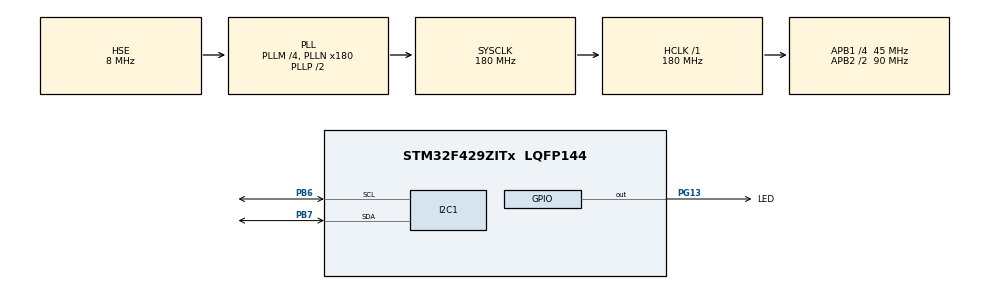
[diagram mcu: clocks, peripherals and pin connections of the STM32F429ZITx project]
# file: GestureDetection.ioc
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Mcu.Family=STM32F4
Mcu.Name=STM32F429ZITx
Mcu.Package=LQFP144
NVIC.PriorityGroup=NVIC_PRIORITYGROUP_4
PB6.Mode=I2C
PB6.Signal=I2C1_SCL
PB7.Mode=I2C
PB7.Signal=I2C1_SDA
PG13.GPIO_Label=LED
PG13.Signal=GPIO_Output
PH0/OSC_IN.Mode=HSE-External-Oscillator
PH0/OSC_IN.Signal=RCC_OSC_IN
PH1/OSC_OUT.Mode=HSE-External-Oscillator
PH1/OSC_OUT.Signal=RCC_OSC_OUT
ProjectManager.HeapSize=0x200
ProjectManager.StackSize=0x400
ProjectManager.TargetToolchain=SW4STM32
RCC.48MHZClocksFreq_Value=90000000
RCC.AHBFreq_Value=180000000
RCC.APB1CLKDivider=RCC_HCLK_DIV4
RCC.APB1Freq_Value=45000000
RCC.APB1TimFreq_Value=90000000
RCC.APB2CLKDivider=RCC_HCLK_DIV2
RCC.APB2Freq_Value=90000000
RCC.APB2TimFreq_Value=180000000
RCC.CortexFreq_Value=180000000
RCC.HCLKFreq_Value=180000000
RCC.HSE_VALUE=8000000
RCC.HSI_VALUE=16000000
RCC.LSE_VALUE=32768
RCC.PLLM=4
RCC.PLLN=180
RCC.PLLSourceVirtual=RCC_PLLSOURCE_HSE
RCC.SYSCLKFreq_VALUE=180000000
RCC.SYSCLKSource=RCC_SYSCLKSOURCE_PLLCLK
RCC.VCOOutputFreq_Value=360000000
board=GestureDetection

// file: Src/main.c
/**
  ******************************************************************************
  * @file           : main.c
  * @brief          : Main program body
  ******************************************************************************
  ** This notice applies to any and all portions of this file
  * that are not between comment pairs USER CODE BEGIN and
  * USER CODE END. Other portions of this file, whether
  * inserted by the user or by software development tools
  * are owned by their respective copyright owners.
  *
  * COPYRIGHT(c) 2018 STMicroelectronics
  *
  * Redistribution and use in source and binary forms, with or without modification,
  * are permitted provided that the following conditions are met:
  *   1. Redistributions of source code must retain the above copyright notice,
  *      this list of conditions and the following disclaimer.
  *   2. Redistributions in binary form must reproduce the above copyright notice,
  *      this list of conditions and the following disclaimer in the documentation
  *      and/or other materials provided with the distribution.
  *   3. Neither the name of STMicroelectronics nor the names of its contributors
  *      may be used to endorse or promote products derived from this software
  *      without specific prior written permission.
  *
  * THIS SOFTWARE IS PROVIDED BY THE COPYRIGHT HOLDERS AND CONTRIBUTORS "AS IS"
  * AND ANY EXPRESS OR IMPLIED WARRANTIES, INCLUDING, BUT NOT LIMITED TO, THE
  * IMPLIED WARRANTIES OF MERCHANTABILITY AND FITNESS FOR A PARTICULAR PURPOSE ARE
  * DISCLAIMED. IN NO EVENT SHALL THE COPYRIGHT HOLDER OR CONTRIBUTORS BE LIABLE
  * FOR ANY DIRECT, INDIRECT, INCIDENTAL, SPECIAL, EXEMPLARY, OR CONSEQUENTIAL
  * DAMAGES (INCLUDING, BUT NOT LIMITED TO, PROCUREMENT OF SUBSTITUTE GOODS OR
  * SERVICES; LOSS OF USE, DATA, OR PROFITS; OR BUSINESS INTERRUPTION) HOWEVER
  * CAUSED AND ON ANY THEORY OF LIABILITY, WHETHER IN CONTRACT, STRICT LIABILITY,
  * OR TORT (INCLUDING NEGLIGENCE OR OTHERWISE) ARISING IN ANY WAY OUT OF THE USE
  * OF THIS SOFTWARE, EVEN IF ADVISED OF THE POSSIBILITY OF SUCH DAMAGE.
  *
  ******************************************************************************
  */
#include "main.h"
#include "stm32f4xx_hal.h"

/* USER CODE BEGIN Includes */
#include "Sensor.h"
/* USER CODE END Includes */

I2C_HandleTypeDef hi2c1;

/* USER CODE BEGIN PV */
/* Private variables ---------------------------------------------------------*/
//#define APDS9960_ADDRESS 0x39
/* USER CODE END PV */

void SystemClock_Config(void);
static void MX_GPIO_Init(void);
static void MX_I2C1_Init(void);

/* USER CODE BEGIN PFP */
/* Private function prototypes -----------------------------------------------*/

/* USER CODE END PFP */

int main(void)
{
  /* USER CODE BEGIN 1 */
	uint8_t data;
//	uint8_t i;
  /* USER CODE END 1 */

  /* MCU Configuration----------------------------------------------------------*/

  /* Reset of all peripherals, Initializes the Flash interface and the Systick. */
  HAL_Init();

  /* Configure the system clock */
  SystemClock_Config();

  /* Initialize all configured peripherals */
  MX_GPIO_Init();
  MX_I2C1_Init();
  /* USER CODE BEGIN 2 */
//  data[0] = APDS9960_ENABLE;
//  data[1] = 0x01;
//
//  if(HAL_I2C_Master_Transmit(&hi2c3,APDS9960_I2C_ADDRESS,data,2,10) == HAL_OK)
//	  HAL_GPIO_TogglePin(GPIOG, GPIO_PIN_13);
//
//  data[0] = APDS9960_ENABLE;
//  if(HAL_I2C_Master_Transmit(&hi2c3,APDS9960_I2C_ADDRESS,data,1,10) == HAL_OK)
//	  HAL_GPIO_TogglePin(GPIOG, GPIO_PIN_13);
//
//  data[1] = 0x00;
//  if(HAL_I2C_Master_Receive(&hi2c3,APDS9960_I2C_ADDRESS,&data[1],1,10) == HAL_OK)
//	  HAL_GPIO_TogglePin(GPIOG, GPIO_PIN_13);
//  if(data[1]==0x01)
//	  HAL_GPIO_TogglePin(GPIOG, GPIO_PIN_13);

//
//  data = 0x01;
//  HAL_I2C_Mem_Write(&hi2c3,APDS9960_I2C_ADDRESS,APDS9960_ENABLE,1,&data,1,100);
  //  for(i=0;i<255;i++){
//	  if(HAL_I2C_IsDeviceReady(&hi2c3,APDS9960_I2C_ADDRESS,5,100) == HAL_OK)
//		  HAL_GPIO_TogglePin(GPIOG, GPIO_PIN_13);
//  }
//  HAL_I2C_Mem_Read(&hi2c3, APDS9960_I2C_ADDRESS, APDS9960_DEVICE_ID, 1, &data, 1, 100);
//
//  if(data == 0x01){		//DEVICE_ID = 0xAB || 0x9C
//	  HAL_GPIO_TogglePin(GPIOG, GPIO_PIN_13);
//  }
  /* USER CODE END 2 */

  /* Infinite loop */
  while (1)
  {

  /* USER CODE BEGIN 3 */
	  /*Mozliwe przyczyny braku polaczenia z sensorem:
	   * - zle ustawiona predkosc i2c
	   * - nalezy najpierw aktywowac sensor (cos mu wyslac)
	   * - funkcja i2c_HAL nie spelnia wymogow sensora (transakcja i2c)
	   * - sensor zle zasilany
	   * -zla konfiguracja zegara w Cube*/
	  if(HAL_I2C_IsDeviceReady(&hi2c1,APDS9960_I2C_ADDRESS,1,50) == HAL_OK)
		  HAL_GPIO_TogglePin(GPIOG, GPIO_PIN_13);
  }
  /* USER CODE END 3 */

}

void SystemClock_Config(void)
{

  RCC_OscInitTypeDef RCC_OscInitStruct;
  RCC_ClkInitTypeDef RCC_ClkInitStruct;

    /**Configure the main internal regulator output voltage
    */
  __HAL_RCC_PWR_CLK_ENABLE();

  __HAL_PWR_VOLTAGESCALING_CONFIG(PWR_REGULATOR_VOLTAGE_SCALE1);

    /**Initializes the CPU, AHB and APB busses clocks
    */
  RCC_OscInitStruct.OscillatorType = RCC_OSCILLATORTYPE_HSE;
  RCC_OscInitStruct.HSEState = RCC_HSE_ON;
  RCC_OscInitStruct.PLL.PLLState = RCC_PLL_ON;
  RCC_OscInitStruct.PLL.PLLSource = RCC_PLLSOURCE_HSE;
  RCC_OscInitStruct.PLL.PLLM = 4;
  RCC_OscInitStruct.PLL.PLLN = 180;
  RCC_OscInitStruct.PLL.PLLP = RCC_PLLP_DIV2;
  RCC_OscInitStruct.PLL.PLLQ = 4;
  if (HAL_RCC_OscConfig(&RCC_OscInitStruct) != HAL_OK)
  {
    _Error_Handler(__FILE__, __LINE__);
  }

    /**Activate the Over-Drive mode
    */
  if (HAL_PWREx_EnableOverDrive() != HAL_OK)
  {
    _Error_Handler(__FILE__, __LINE__);
  }

    /**Initializes the CPU, AHB and APB busses clocks
    */
  RCC_ClkInitStruct.ClockType = RCC_CLOCKTYPE_HCLK|RCC_CLOCKTYPE_SYSCLK
                              |RCC_CLOCKTYPE_PCLK1|RCC_CLOCKTYPE_PCLK2;
  RCC_ClkInitStruct.SYSCLKSource = RCC_SYSCLKSOURCE_PLLCLK;
  RCC_ClkInitStruct.AHBCLKDivider = RCC_SYSCLK_DIV1;
  RCC_ClkInitStruct.APB1CLKDivider = RCC_HCLK_DIV4;
  RCC_ClkInitStruct.APB2CLKDivider = RCC_HCLK_DIV2;

  if (HAL_RCC_ClockConfig(&RCC_ClkInitStruct, FLASH_LATENCY_5) != HAL_OK)
  {
    _Error_Handler(__FILE__, __LINE__);
  }

    /**Configure the Systick interrupt time
    */
  HAL_SYSTICK_Config(HAL_RCC_GetHCLKFreq()/1000);

    /**Configure the Systick
    */
  HAL_SYSTICK_CLKSourceConfig(SYSTICK_CLKSOURCE_HCLK);

  /* SysTick_IRQn interrupt configuration */
  HAL_NVIC_SetPriority(SysTick_IRQn, 0, 0);
}

/* I2C1 init function */
static void MX_I2C1_Init(void)
{

  hi2c1.Instance = I2C1;
  hi2c1.Init.ClockSpeed = 100000;
  hi2c1.Init.DutyCycle = I2C_DUTYCYCLE_2;
  hi2c1.Init.OwnAddress1 = 0;
  hi2c1.Init.AddressingMode = I2C_ADDRESSINGMODE_7BIT;
  hi2c1.Init.DualAddressMode = I2C_DUALADDRESS_DISABLE;
  hi2c1.Init.OwnAddress2 = 0;
  hi2c1.Init.GeneralCallMode = I2C_GENERALCALL_DISABLE;
  hi2c1.Init.NoStretchMode = I2C_NOSTRETCH_DISABLE;
  if (HAL_I2C_Init(&hi2c1) != HAL_OK)
  {
    _Error_Handler(__FILE__, __LINE__);
  }

}

/** Configure pins as
        * Analog
        * Input
        * Output
        * EVENT_OUT
        * EXTI
*/
static void MX_GPIO_Init(void)
{

  GPIO_InitTypeDef GPIO_InitStruct;

  /* GPIO Ports Clock Enable */
  __HAL_RCC_GPIOH_CLK_ENABLE();
  __HAL_RCC_GPIOG_CLK_ENABLE();
  __HAL_RCC_GPIOB_CLK_ENABLE();

  /*Configure GPIO pin Output Level */
  HAL_GPIO_WritePin(LED_GPIO_Port, LED_Pin, GPIO_PIN_RESET);

  /*Configure GPIO pin : LED_Pin */
  GPIO_InitStruct.Pin = LED_Pin;
  GPIO_InitStruct.Mode = GPIO_MODE_OUTPUT_PP;
  GPIO_InitStruct.Pull = GPIO_NOPULL;
  GPIO_InitStruct.Speed = GPIO_SPEED_FREQ_LOW;
  HAL_GPIO_Init(LED_GPIO_Port, &GPIO_InitStruct);

}

void _Error_Handler(char *file, int line)
{
  while(1)
  {
  }
}

/************************ (C) COPYRIGHT STMicroelectronics *****END OF FILE****/
